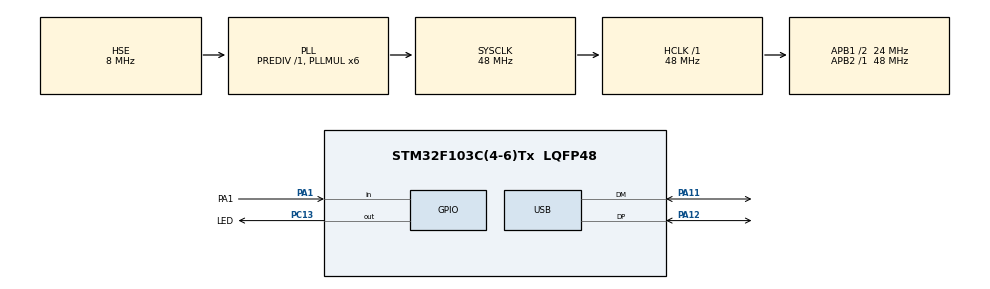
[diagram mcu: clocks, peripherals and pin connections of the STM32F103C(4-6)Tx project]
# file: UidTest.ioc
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Mcu.Family=STM32F1
Mcu.Name=STM32F103C(4-6)Tx
Mcu.Package=LQFP48
NVIC.PriorityGroup=NVIC_PRIORITYGROUP_4
NVIC.USB_LP_CAN1_RX0_IRQn=true\:0\:0\:false\:false\:true\:false\:true\:true
PA1.GPIO_Label=PA1
PA1.Signal=GPIO_Input
PA11.Mode=Device
PA11.Signal=USB_DM
PA12.Mode=Device
PA12.Signal=USB_DP
PA13.Mode=Serial_Wire
PA13.Signal=SYS_JTMS-SWDIO
PA14.Mode=Serial_Wire
PA14.Signal=SYS_JTCK-SWCLK
PC13-TAMPER-RTC.GPIO_Label=LED
PC13-TAMPER-RTC.Signal=GPIO_Output
PD0-OSC_IN.Mode=HSE-External-Oscillator
PD0-OSC_IN.Signal=RCC_OSC_IN
PD1-OSC_OUT.Mode=HSE-External-Oscillator
PD1-OSC_OUT.Signal=RCC_OSC_OUT
ProjectManager.HeapSize=0x200
ProjectManager.StackSize=0x400
ProjectManager.TargetToolchain=MDK-ARM V5.32
RCC.AHBFreq_Value=48000000
RCC.APB1CLKDivider=RCC_HCLK_DIV2
RCC.APB1Freq_Value=24000000
RCC.APB1TimFreq_Value=48000000
RCC.APB2Freq_Value=48000000
RCC.APB2TimFreq_Value=48000000
RCC.HCLKFreq_Value=48000000
RCC.PLLMUL=RCC_PLL_MUL6
RCC.SYSCLKFreq_VALUE=48000000
RCC.SYSCLKSource=RCC_SYSCLKSOURCE_PLLCLK
RCC.USBFreq_Value=48000000
USB_DEVICE.CLASS_NAME_FS=HID
USB_DEVICE.VirtualMode=Hid
USB_DEVICE.VirtualModeFS=Hid_FS
VP_USB_DEVICE_VS_USB_DEVICE_HID_FS.Mode=HID_FS
board=custom

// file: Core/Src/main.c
/* USER CODE BEGIN Header */
/**
  ******************************************************************************
  * @file           : main.c
  * @brief          : Main program body
  ******************************************************************************
  * @attention
  *
  * Copyright (c) 2022 STMicroelectronics.
  * All rights reserved.
  *
  * This software is licensed under terms that can be found in the LICENSE file
  * in the root directory of this software component.
  * If no LICENSE file comes with this software, it is provided AS-IS.
  *
  ******************************************************************************
  */
/* USER CODE END Header */
#include "main.h"
#include "usb_device.h"
#include "gpio.h"
#include "usbd_hid.h"

/* USER CODE BEGIN PV */
/*
字节1：无符号字符型，低三位分别表示鼠标的左、右、中键是否被按下，1按下，0抬起。
字节2：有符号字符型，表示鼠标在x方向的移动。
字节3：有符号字符型，表示鼠标在y方向的移动。
字节4：有符号字符型，表示鼠标滚轮的移动。
*/
uint8_t MouseData01[4] = {0,0,0,0};
GPIO_PinState lastState = GPIO_PIN_RESET;
extern USBD_HandleTypeDef hUsbDeviceFS;
/* USER CODE END PV */

void SystemClock_Config(void);

int main(void)
{

  /* MCU Configuration--------------------------------------------------------*/

  /* Reset of all peripherals, Initializes the Flash interface and the Systick. */
  HAL_Init();

  /* Configure the system clock */
  SystemClock_Config();

  /* Initialize all configured peripherals */
  MX_GPIO_Init();
  MX_USB_DEVICE_Init();

  /* Infinite loop */
  while (1)
  {
		GPIO_PinState state = HAL_GPIO_ReadPin(PA1_GPIO_Port,PA1_Pin);

		if(state == GPIO_PIN_SET)
			HAL_GPIO_WritePin(LED_GPIO_Port,LED_Pin,GPIO_PIN_RESET);//low = led on
		else
			HAL_GPIO_WritePin(LED_GPIO_Port,LED_Pin,GPIO_PIN_SET);

		if(state != lastState)
		{
			if(state == GPIO_PIN_SET) //switch pressed
				MouseData01[0] = 0b00000001; // |0 0 0 0|0 middle right left| //https://www.usb.org/sites/default/files/hid1_11.pdf
			else
				MouseData01[0] = 0b00000000;

			USBD_HID_SendReport(&hUsbDeviceFS,(uint8_t*)&MouseData01,sizeof(MouseData01));

			lastState = state;
		}
  }
}

void SystemClock_Config(void)
{
  RCC_OscInitTypeDef RCC_OscInitStruct = {0};
  RCC_ClkInitTypeDef RCC_ClkInitStruct = {0};
  RCC_PeriphCLKInitTypeDef PeriphClkInit = {0};

  /** Initializes the RCC Oscillators according to the specified parameters
  * in the RCC_OscInitTypeDef structure.
  */
  RCC_OscInitStruct.OscillatorType = RCC_OSCILLATORTYPE_HSE;
  RCC_OscInitStruct.HSEState = RCC_HSE_ON;
  RCC_OscInitStruct.HSEPredivValue = RCC_HSE_PREDIV_DIV1;
  RCC_OscInitStruct.HSIState = RCC_HSI_ON;
  RCC_OscInitStruct.PLL.PLLState = RCC_PLL_ON;
  RCC_OscInitStruct.PLL.PLLSource = RCC_PLLSOURCE_HSE;
  RCC_OscInitStruct.PLL.PLLMUL = RCC_PLL_MUL6;
  if (HAL_RCC_OscConfig(&RCC_OscInitStruct) != HAL_OK)
  {
    Error_Handler();
  }

  /** Initializes the CPU, AHB and APB buses clocks
  */
  RCC_ClkInitStruct.ClockType = RCC_CLOCKTYPE_HCLK|RCC_CLOCKTYPE_SYSCLK
                              |RCC_CLOCKTYPE_PCLK1|RCC_CLOCKTYPE_PCLK2;
  RCC_ClkInitStruct.SYSCLKSource = RCC_SYSCLKSOURCE_PLLCLK;
  RCC_ClkInitStruct.AHBCLKDivider = RCC_SYSCLK_DIV1;
  RCC_ClkInitStruct.APB1CLKDivider = RCC_HCLK_DIV2;
  RCC_ClkInitStruct.APB2CLKDivider = RCC_HCLK_DIV1;

  if (HAL_RCC_ClockConfig(&RCC_ClkInitStruct, FLASH_LATENCY_1) != HAL_OK)
  {
    Error_Handler();
  }
  PeriphClkInit.PeriphClockSelection = RCC_PERIPHCLK_USB;
  PeriphClkInit.UsbClockSelection = RCC_USBCLKSOURCE_PLL;
  if (HAL_RCCEx_PeriphCLKConfig(&PeriphClkInit) != HAL_OK)
  {
    Error_Handler();
  }
}

void Error_Handler(void)
{
  __disable_irq();
  while (1)
  {
  }
}
